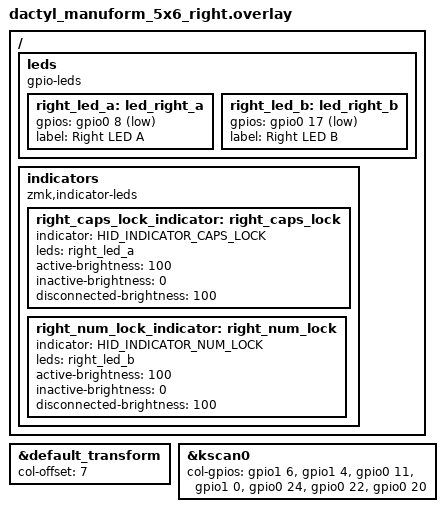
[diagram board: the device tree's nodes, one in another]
#include "dactyl_manuform_5x6.dtsi"
#include <dt-bindings/zmk/hid_indicators.h>

&default_transform { // The matrix transform for this board is 6 columns over because the left half is 6 columns wide according to the matrix.
    col-offset = <7>;
};

&kscan0 {
    col-gpios
        = <&gpio1 6 GPIO_ACTIVE_HIGH>
        , <&gpio1 4 GPIO_ACTIVE_HIGH>
        , <&gpio0 11 GPIO_ACTIVE_HIGH>
        , <&gpio1 0 GPIO_ACTIVE_HIGH>
        , <&gpio0 24 GPIO_ACTIVE_HIGH>
        , <&gpio0 22 GPIO_ACTIVE_HIGH>
        , <&gpio0 20 GPIO_ACTIVE_HIGH>
        ;
};


/ {
	leds {
		compatible = "gpio-leds";

		right_led_a: led_right_a {
			gpios = <&gpio0 8 GPIO_ACTIVE_LOW>;
			label = "Right LED A";
		};

		right_led_b: led_right_b {
			gpios = <&gpio0 17 GPIO_ACTIVE_LOW>;
			label = "Right LED B";
		};
	};

	indicators {
		compatible = "zmk,indicator-leds";

		right_caps_lock_indicator: right_caps_lock {
			indicator = <HID_INDICATOR_CAPS_LOCK>;
			leds = <&right_led_a>;
			active-brightness = <100>;
			inactive-brightness = <0>;
			disconnected-brightness = <100>;
		};

		right_num_lock_indicator: right_num_lock {
			indicator = <HID_INDICATOR_NUM_LOCK>;
			leds = <&right_led_b>;
			active-brightness = <100>;
			inactive-brightness = <0>;
			disconnected-brightness = <100>;
		};
	};
};
